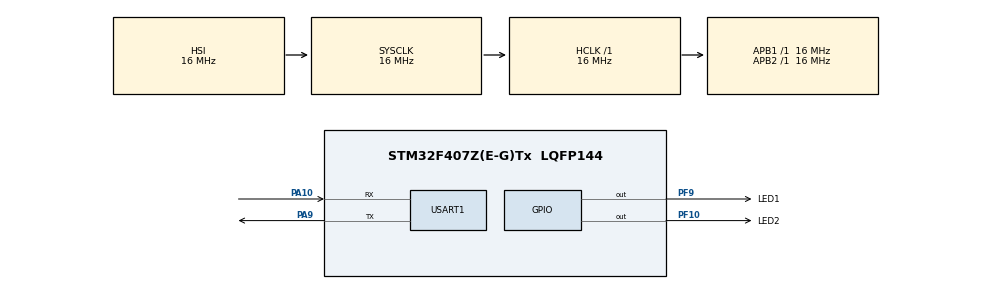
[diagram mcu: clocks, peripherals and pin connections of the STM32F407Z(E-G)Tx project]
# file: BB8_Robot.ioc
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Dma.Request0=USART1_RX
Dma.USART1_RX.0.Direction=DMA_PERIPH_TO_MEMORY
Dma.USART1_RX.0.FIFOMode=DMA_FIFOMODE_DISABLE
Dma.USART1_RX.0.Instance=DMA2_Stream2
Dma.USART1_RX.0.MemDataAlignment=DMA_MDATAALIGN_BYTE
Dma.USART1_RX.0.MemInc=DMA_MINC_ENABLE
Dma.USART1_RX.0.Mode=DMA_NORMAL
Dma.USART1_RX.0.PeriphDataAlignment=DMA_PDATAALIGN_BYTE
Dma.USART1_RX.0.PeriphInc=DMA_PINC_DISABLE
Dma.USART1_RX.0.Priority=DMA_PRIORITY_LOW
FREERTOS.Tasks01=TASK_LED,-1,128,Task_LED,Default,NULL,Dynamic,NULL,NULL
Mcu.Family=STM32F4
Mcu.Name=STM32F407Z(E-G)Tx
Mcu.Package=LQFP144
NVIC.DMA2_Stream2_IRQn=true\:5\:0\:false\:false\:true\:true\:false
NVIC.PriorityGroup=NVIC_PRIORITYGROUP_4
NVIC.TIM1_UP_TIM10_IRQn=true\:0\:0\:false\:false\:true\:false\:false
NVIC.TimeBase=TIM1_UP_TIM10_IRQn
NVIC.TimeBaseIP=TIM1
PA10.Mode=Asynchronous
PA10.Signal=USART1_RX
PA9.Mode=Asynchronous
PA9.Signal=USART1_TX
PF10.GPIO_Label=LED2
PF10.GPIO_PuPd=GPIO_NOPULL
PF10.Signal=GPIO_Output
PF9.GPIO_Label=LED1
PF9.GPIO_PuPd=GPIO_NOPULL
PF9.Signal=GPIO_Output
PH0-OSC_IN.Mode=HSE-External-Oscillator
PH0-OSC_IN.Signal=RCC_OSC_IN
PH1-OSC_OUT.Mode=HSE-External-Oscillator
PH1-OSC_OUT.Signal=RCC_OSC_OUT
ProjectManager.HeapSize=0x200
ProjectManager.StackSize=0x400
ProjectManager.TargetToolchain=MDK-ARM V5
RCC.AHBFreq_Value=16000000
RCC.APB1Freq_Value=16000000
RCC.APB1TimFreq_Value=16000000
RCC.APB2Freq_Value=16000000
RCC.APB2TimFreq_Value=16000000
RCC.CortexFreq_Value=16000000
RCC.HCLKFreq_Value=16000000
RCC.HSE_VALUE=25000000
RCC.HSI_VALUE=16000000
RCC.LSE_VALUE=32768
RCC.SYSCLKFreq_VALUE=16000000
RCC.VCOOutputFreq_Value=192000000
USART1.StopBits=STOPBITS_1
USART1.VirtualMode=VM_ASYNC
VP_FREERTOS_VS_ENABLE.Mode=Enabled
VP_SYS_VS_tim1.Mode=TIM1
board=custom

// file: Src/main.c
/**
  ******************************************************************************
  * @file           : main.c
  * @brief          : Main program body
  ******************************************************************************
  * This notice applies to any and all portions of this file
  * that are not between comment pairs USER CODE BEGIN and
  * USER CODE END. Other portions of this file, whether
  * inserted by the user or by software development tools
  * are owned by their respective copyright owners.
  *
  * Copyright (c) 2019 STMicroelectronics International N.V.
  * All rights reserved.
  *
  * Redistribution and use in source and binary forms, with or without
  * modification, are permitted, provided that the following conditions are met:
  *
  * 1. Redistribution of source code must retain the above copyright notice,
  *    this list of conditions and the following disclaimer.
  * 2. Redistributions in binary form must reproduce the above copyright notice,
  *    this list of conditions and the following disclaimer in the documentation
  *    and/or other materials provided with the distribution.
  * 3. Neither the name of STMicroelectronics nor the names of other
  *    contributors to this software may be used to endorse or promote products
  *    derived from this software without specific written permission.
  * 4. This software, including modifications and/or derivative works of this
  *    software, must execute solely and exclusively on microcontroller or
  *    microprocessor devices manufactured by or for STMicroelectronics.
  * 5. Redistribution and use of this software other than as permitted under
  *    this license is void and will automatically terminate your rights under
  *    this license.
  *
  * THIS SOFTWARE IS PROVIDED BY STMICROELECTRONICS AND CONTRIBUTORS "AS IS"
  * AND ANY EXPRESS, IMPLIED OR STATUTORY WARRANTIES, INCLUDING, BUT NOT
  * LIMITED TO, THE IMPLIED WARRANTIES OF MERCHANTABILITY, FITNESS FOR A
  * PARTICULAR PURPOSE AND NON-INFRINGEMENT OF THIRD PARTY INTELLECTUAL PROPERTY
  * RIGHTS ARE DISCLAIMED TO THE FULLEST EXTENT PERMITTED BY LAW. IN NO EVENT
  * SHALL STMICROELECTRONICS OR CONTRIBUTORS BE LIABLE FOR ANY DIRECT, INDIRECT,
  * INCIDENTAL, SPECIAL, EXEMPLARY, OR CONSEQUENTIAL DAMAGES (INCLUDING, BUT NOT
  * LIMITED TO, PROCUREMENT OF SUBSTITUTE GOODS OR SERVICES; LOSS OF USE, DATA,
  * OR PROFITS; OR BUSINESS INTERRUPTION) HOWEVER CAUSED AND ON ANY THEORY OF
  * LIABILITY, WHETHER IN CONTRACT, STRICT LIABILITY, OR TORT (INCLUDING
  * NEGLIGENCE OR OTHERWISE) ARISING IN ANY WAY OUT OF THE USE OF THIS SOFTWARE,
  * EVEN IF ADVISED OF THE POSSIBILITY OF SUCH DAMAGE.
  *
  ******************************************************************************
  */
#include "main.h"
#include "stm32f4xx_hal.h"
#include "cmsis_os.h"
#include "dma.h"
#include "usart.h"
#include "gpio.h"

/* USER CODE BEGIN PV */
/* Private variables ---------------------------------------------------------*/

/* USER CODE END PV */

void SystemClock_Config(void);
void MX_FREERTOS_Init(void);

/* USER CODE BEGIN PFP */
/* Private function prototypes -----------------------------------------------*/

/* USER CODE END PFP */

int main(void)
{

  /* MCU Configuration----------------------------------------------------------*/

  /* Reset of all peripherals, Initializes the Flash interface and the Systick. */
  HAL_Init();

  /* Configure the system clock */
  SystemClock_Config();

  /* Initialize all configured peripherals */
  MX_GPIO_Init();
  MX_DMA_Init();
  MX_USART1_UART_Init();

  /* Call init function for freertos objects (in freertos.c) */
  MX_FREERTOS_Init();

  /* Start scheduler */
  osKernelStart();

  /* We should never get here as control is now taken by the scheduler */

  /* Infinite loop */
  while (1)
  {

  }

}

void SystemClock_Config(void)
{

  RCC_OscInitTypeDef RCC_OscInitStruct;
  RCC_ClkInitTypeDef RCC_ClkInitStruct;

    /**Configure the main internal regulator output voltage
    */
  __HAL_RCC_PWR_CLK_ENABLE();

  __HAL_PWR_VOLTAGESCALING_CONFIG(PWR_REGULATOR_VOLTAGE_SCALE1);

    /**Initializes the CPU, AHB and APB busses clocks
    */
  RCC_OscInitStruct.OscillatorType = RCC_OSCILLATORTYPE_HSI;
  RCC_OscInitStruct.HSIState = RCC_HSI_ON;
  RCC_OscInitStruct.HSICalibrationValue = 16;
  RCC_OscInitStruct.PLL.PLLState = RCC_PLL_NONE;
  if (HAL_RCC_OscConfig(&RCC_OscInitStruct) != HAL_OK)
  {
    _Error_Handler(__FILE__, __LINE__);
  }

    /**Initializes the CPU, AHB and APB busses clocks
    */
  RCC_ClkInitStruct.ClockType = RCC_CLOCKTYPE_HCLK|RCC_CLOCKTYPE_SYSCLK
                              |RCC_CLOCKTYPE_PCLK1|RCC_CLOCKTYPE_PCLK2;
  RCC_ClkInitStruct.SYSCLKSource = RCC_SYSCLKSOURCE_HSI;
  RCC_ClkInitStruct.AHBCLKDivider = RCC_SYSCLK_DIV1;
  RCC_ClkInitStruct.APB1CLKDivider = RCC_HCLK_DIV1;
  RCC_ClkInitStruct.APB2CLKDivider = RCC_HCLK_DIV1;

  if (HAL_RCC_ClockConfig(&RCC_ClkInitStruct, FLASH_LATENCY_0) != HAL_OK)
  {
    _Error_Handler(__FILE__, __LINE__);
  }

    /**Configure the Systick interrupt time
    */
  HAL_SYSTICK_Config(HAL_RCC_GetHCLKFreq()/1000);

    /**Configure the Systick
    */
  HAL_SYSTICK_CLKSourceConfig(SYSTICK_CLKSOURCE_HCLK);

  /* SysTick_IRQn interrupt configuration */
  HAL_NVIC_SetPriority(SysTick_IRQn, 15, 0);
}

void HAL_TIM_PeriodElapsedCallback(TIM_HandleTypeDef *htim)
{
  if (htim->Instance == TIM1) {
    HAL_IncTick();
  }
}

uint8_t error_flag =0;
void _Error_Handler(char *file, int line)
{
  /* USER CODE BEGIN Error_Handler_Debug */
  /* User can add his own implementation to report the HAL error return state */
  while(1)
  {
		error_flag = 1;
  }
  /* USER CODE END Error_Handler_Debug */
}

/************************ (C) COPYRIGHT STMicroelectronics *****END OF FILE****/

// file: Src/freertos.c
/**
  ******************************************************************************
  * File Name          : freertos.c
  * Description        : Code for freertos applications
  ******************************************************************************
  * This notice applies to any and all portions of this file
  * that are not between comment pairs USER CODE BEGIN and
  * USER CODE END. Other portions of this file, whether
  * inserted by the user or by software development tools
  * are owned by their respective copyright owners.
  *
  * Copyright (c) 2019 STMicroelectronics International N.V.
  * All rights reserved.
  *
  * Redistribution and use in source and binary forms, with or without
  * modification, are permitted, provided that the following conditions are met:
  *
  * 1. Redistribution of source code must retain the above copyright notice,
  *    this list of conditions and the following disclaimer.
  * 2. Redistributions in binary form must reproduce the above copyright notice,
  *    this list of conditions and the following disclaimer in the documentation
  *    and/or other materials provided with the distribution.
  * 3. Neither the name of STMicroelectronics nor the names of other
  *    contributors to this software may be used to endorse or promote products
  *    derived from this software without specific written permission.
  * 4. This software, including modifications and/or derivative works of this
  *    software, must execute solely and exclusively on microcontroller or
  *    microprocessor devices manufactured by or for STMicroelectronics.
  * 5. Redistribution and use of this software other than as permitted under
  *    this license is void and will automatically terminate your rights under
  *    this license.
  *
  * THIS SOFTWARE IS PROVIDED BY STMICROELECTRONICS AND CONTRIBUTORS "AS IS"
  * AND ANY EXPRESS, IMPLIED OR STATUTORY WARRANTIES, INCLUDING, BUT NOT
  * LIMITED TO, THE IMPLIED WARRANTIES OF MERCHANTABILITY, FITNESS FOR A
  * PARTICULAR PURPOSE AND NON-INFRINGEMENT OF THIRD PARTY INTELLECTUAL PROPERTY
  * RIGHTS ARE DISCLAIMED TO THE FULLEST EXTENT PERMITTED BY LAW. IN NO EVENT
  * SHALL STMICROELECTRONICS OR CONTRIBUTORS BE LIABLE FOR ANY DIRECT, INDIRECT,
  * INCIDENTAL, SPECIAL, EXEMPLARY, OR CONSEQUENTIAL DAMAGES (INCLUDING, BUT NOT
  * LIMITED TO, PROCUREMENT OF SUBSTITUTE GOODS OR SERVICES; LOSS OF USE, DATA,
  * OR PROFITS; OR BUSINESS INTERRUPTION) HOWEVER CAUSED AND ON ANY THEORY OF
  * LIABILITY, WHETHER IN CONTRACT, STRICT LIABILITY, OR TORT (INCLUDING
  * NEGLIGENCE OR OTHERWISE) ARISING IN ANY WAY OUT OF THE USE OF THIS SOFTWARE,
  * EVEN IF ADVISED OF THE POSSIBILITY OF SUCH DAMAGE.
  *
  ******************************************************************************
  */

#include "FreeRTOS.h"
#include "task.h"
#include "cmsis_os.h"

osThreadId TASK_LEDHandle;

void Task_LED(void const * argument);

void MX_FREERTOS_Init(void); /* (MISRA C 2004 rule 8.1) */

/* Hook prototypes */

/* Init FreeRTOS */

void MX_FREERTOS_Init(void) {

  /* Create the thread(s) */
  /* definition and creation of TASK_LED */
  osThreadDef(TASK_LED, Task_LED, osPriorityBelowNormal, 0, 128);
  TASK_LEDHandle = osThreadCreate(osThread(TASK_LED), NULL);

}

/* Task_LED function */

/************************ (C) COPYRIGHT STMicroelectronics *****END OF FILE****/
